AUTOSAR XML (schema 4-2-2)
standard types defined: boolean, float32, float64, sint16, sint32, sint64, sint8, uint16, uint32, uint64, uint8, void
package /BSW/ImplementationDataTypes
  57 x impl type:
    Dcm_ConfirmationStatusType: compu {0x00=DCM_RES_POS_OK, 0x01=DCM_RES_POS_NOT_OK, 0x02=DCM_RES_NEG_OK, 0x03=DCM_RES_NEG_NOT_OK}, implementation-data-type=uint8
    Dcm_DataElement_DspData_0xF010_0Type: implementation-data-type=Dcm_DataElement_DspData_0xF010_0_ArrayType
    Dcm_DataElement_DspData_0xF010_0_ArrayType: category=ARRAY
      element SubElement: array-size=4, array-size-semantics=FIXED-SIZE, implementation-data-type=uint8
    Dcm_DataElement_DspData_0xF110_0Type: implementation-data-type=Dcm_DataElement_DspData_0xF110_0_ArrayType
    Dcm_DataElement_DspData_0xF110_0_ArrayType: category=ARRAY
      element SubElement: array-size=11, array-size-semantics=FIXED-SIZE, implementation-data-type=uint8
    Dcm_DataElement_DspData_0xF111_0Type: implementation-data-type=Dcm_DataElement_DspData_0xF111_0_ArrayType
    Dcm_DataElement_DspData_0xF111_0_ArrayType: category=ARRAY
      element SubElement: array-size=2, array-size-semantics=FIXED-SIZE, implementation-data-type=uint8
    Dcm_DataElement_DspData_0xF118_0Type: implementation-data-type=Dcm_DataElement_DspData_0xF118_0_ArrayType
    Dcm_DataElement_DspData_0xF118_0_ArrayType: category=ARRAY
      element SubElement: array-size=11, array-size-semantics=FIXED-SIZE, implementation-data-type=uint8
    Dcm_DataElement_DspData_0xF119_0Type: implementation-data-type=Dcm_DataElement_DspData_0xF119_0_ArrayType
    Dcm_DataElement_DspData_0xF119_0_ArrayType: category=ARRAY
      element SubElement: array-size=2, array-size-semantics=FIXED-SIZE, implementation-data-type=uint8
    Dcm_DataElement_DspData_0xF150_0Type: implementation-data-type=Dcm_DataElement_DspData_0xF150_0_ArrayType
    Dcm_DataElement_DspData_0xF150_0_ArrayType: category=ARRAY
      element SubElement: array-size=3, array-size-semantics=FIXED-SIZE, implementation-data-type=uint8
    Dcm_DataElement_DspData_0xF15B_0Type: implementation-data-type=Dcm_DataElement_DspData_0xF15B_0_ArrayType
    Dcm_DataElement_DspData_0xF15B_0_ArrayType: category=ARRAY
      element SubElement: array-size=12, array-size-semantics=FIXED-SIZE, implementation-data-type=uint8
    Dcm_DataElement_DspData_0xF186_0Type: implementation-data-type=Dcm_DataElement_DspData_0xF186_0_PrimitiveType
    Dcm_DataElement_DspData_0xF186_0_PrimitiveType: category=VALUE, base-type=uint8
    Dcm_DataElement_DspData_0xF18A_0Type: implementation-data-type=Dcm_DataElement_DspData_0xF18A_0_ArrayType
    Dcm_DataElement_DspData_0xF18A_0_ArrayType: category=ARRAY
      element SubElement: array-size=8, array-size-semantics=FIXED-SIZE, implementation-data-type=uint8
    Dcm_DataElement_DspData_0xF18B_0Type: implementation-data-type=Dcm_DataElement_DspData_0xF18B_0_ArrayType
    Dcm_DataElement_DspData_0xF18B_0_ArrayType: category=ARRAY
      element SubElement: array-size=3, array-size-semantics=FIXED-SIZE, implementation-data-type=uint8
    Dcm_DataElement_DspData_0xF18C_0Type: implementation-data-type=Dcm_DataElement_DspData_0xF18C_0_ArrayType
    Dcm_DataElement_DspData_0xF18C_0_ArrayType: category=ARRAY
      element SubElement: array-size=16, array-size-semantics=FIXED-SIZE, implementation-data-type=uint8
    Dcm_DataElement_DspData_0xF193_0Type: implementation-data-type=Dcm_DataElement_DspData_0xF193_0_ArrayType
    Dcm_DataElement_DspData_0xF193_0_ArrayType: category=ARRAY
      element SubElement: array-size=3, array-size-semantics=FIXED-SIZE, implementation-data-type=uint8
    Dcm_DataElement_DspData_0xF195_0Type: implementation-data-type=Dcm_DataElement_DspData_0xF195_0_ArrayType
    Dcm_DataElement_DspData_0xF195_0_ArrayType: category=ARRAY
      element SubElement: array-size=3, array-size-semantics=FIXED-SIZE, implementation-data-type=uint8
    Dcm_DataElement_DspData_0xF19E_0Type: implementation-data-type=Dcm_DataElement_DspData_0xF19E_0_ArrayType
    Dcm_DataElement_DspData_0xF19E_0_ArrayType: category=ARRAY
      element SubElement: array-size=3, array-size-semantics=FIXED-SIZE, implementation-data-type=uint8
    Dcm_DataElement_DspData_0xFD00_0Type: implementation-data-type=Dcm_DataElement_DspData_0xFD00_0_ArrayType
    Dcm_DataElement_DspData_0xFD00_0_ArrayType: category=ARRAY
      element SubElement: array-size=3, array-size-semantics=FIXED-SIZE, implementation-data-type=uint8
    Dcm_DataElement_DspData_0xFD01_0Type: implementation-data-type=Dcm_DataElement_DspData_0xFD01_0_ArrayType
    Dcm_DataElement_DspData_0xFD01_0_ArrayType: category=ARRAY
      element SubElement: array-size=3, array-size-semantics=FIXED-SIZE, implementation-data-type=uint8
    Dcm_DataElement_DspData_0xFD02_0Type: implementation-data-type=Dcm_DataElement_DspData_0xFD02_0_ArrayType
    Dcm_DataElement_DspData_0xFD02_0_ArrayType: category=ARRAY
      element SubElement: array-size=3, array-size-semantics=FIXED-SIZE, implementation-data-type=uint8
    Dcm_DataElement_DspData_0xFD03_0Type: implementation-data-type=Dcm_DataElement_DspData_0xFD03_0_ArrayType
    Dcm_DataElement_DspData_0xFD03_0_ArrayType: category=ARRAY
      element SubElement: array-size=2, array-size-semantics=FIXED-SIZE, implementation-data-type=uint8
    Dcm_DataElement_DspData_0xFD05_0Type: implementation-data-type=Dcm_DataElement_DspData_0xFD05_0_ArrayType
    Dcm_DataElement_DspData_0xFD05_0_ArrayType: category=ARRAY
      element SubElement: array-size=6, array-size-semantics=FIXED-SIZE, implementation-data-type=uint8
    Dcm_DataElement_DspData_0xFD06_0Type: implementation-data-type=Dcm_DataElement_DspData_0xFD06_0_ArrayType
    Dcm_DataElement_DspData_0xFD06_0_ArrayType: category=ARRAY
      element SubElement: array-size=8, array-size-semantics=FIXED-SIZE, implementation-data-type=uint8
    Dcm_DidSupportedType: compu {0=DCM_DID_SUPPORTED, 1=DCM_DID_NOT_SUPPORTED}, implementation-data-type=uint8
    Dcm_KeyArray_L2Type: category=ARRAY
      element SubElement: array-size=4, array-size-semantics=FIXED-SIZE, implementation-data-type=uint8
    Dcm_NegativeResponseCodeType:
      compu {0x00=DCM_POS_RESP, 0x10=DCM_E_GENERALREJECT, 0x11=DCM_E_SERVICENOTSUPPORTED, 0x12=DCM_E_SUBFUNCTIONNOTSUPPORTED, 0x13=DCM_E_INCORRECTMESSAGELENGTHORINVALIDFORMAT, 0x14=DCM_E_RESPONSETOOLONG, 0x21=DCM_E_BUSYREPEATREQUEST, 0x22=DCM_E_CONDITIONSNOTCORRECT, 0x24=DCM_E_REQUESTSEQUENCEERROR, 0x25=DCM_E_NORESPONSEFROMSUBNETCOMPONENT, 0x26=DCM_E_FAILUREPREVENTSEXECUTIONOFREQUESTEDACTION, 0x31=DCM_E_REQUESTOUTOFRANGE, 0x33=DCM_E_SECURITYACCESSDENIED, 0x35=DCM_E_INVALIDKEY, 0x36=DCM_E_EXCEEDNUMBEROFATTEMPTS, 0x37=DCM_E_REQUIREDTIMEDELAYNOTEXPIRED, 0x70=DCM_E_UPLOADDOWNLOADNOTACCEPTED, 0x71=DCM_E_TRANSFERDATASUSPENDED, 0x72=DCM_E_GENERALPROGRAMMINGFAILURE, 0x73=DCM_E_WRONGBLOCKSEQUENCECOUNTER, 0x7E=DCM_E_SUBFUNCTIONNOTSUPPORTEDINACTIVESESSION, 0x7F=DCM_E_SERVICENOTSUPPORTEDINACTIVESESSION, 0x81=DCM_E_RPMTOOHIGH, 0x82=DCM_E_RPMTOOLOW, 0x83=DCM_E_ENGINEISRUNNING, 0x84=DCM_E_ENGINEISNOTRUNNING, 0x85=DCM_E_ENGINERUNTIMETOOLOW, 0x86=DCM_E_TEMPERATURETOOHIGH, 0x87=DCM_E_TEMPERATURETOOLOW, 0x88=DCM_E_VEHICLESPEEDTOOHIGH, 0x89=DCM_E_VEHICLESPEEDTOOLOW, 0x8A=DCM_E_THROTTLE_PEDALTOOHIGH, 0x8B=DCM_E_THROTTLE_PEDALTOOLOW, 0x8C=DCM_E_TRANSMISSIONRANGENOTINNEUTRAL, 0x8D=DCM_E_TRANSMISSIONRANGENOTINGEAR, 0x8F=DCM_E_BRAKESWITCH_NOTCLOSED, 0x90=DCM_E_SHIFTERLEVERNOTINPARK, 0x91=DCM_E_TORQUECONVERTERCLUTCHLOCKED, 0x92=DCM_E_VOLTAGETOOHIGH, 0x93=DCM_E_VOLTAGETOOLOW, 0xF0=DCM_E_VMSCNC_0, 0xF1=DCM_E_VMSCNC_1, 0xF2=DCM_E_VMSCNC_2, 0xF3=DCM_E_VMSCNC_3, 0xF4=DCM_E_VMSCNC_4, 0xF5=DCM_E_VMSCNC_5, 0xF6=DCM_E_VMSCNC_6, 0xF7=DCM_E_VMSCNC_7, 0xF8=DCM_E_VMSCNC_8, 0xF9=DCM_E_VMSCNC_9, 0xFA=DCM_E_VMSCNC_A, 0xFB=DCM_E_VMSCNC_B, 0xFC=DCM_E_VMSCNC_C, 0xFD=DCM_E_VMSCNC_D, 0xFE=DCM_E_VMSCNC_E}
      range raw 0x00..0xFF
      implementation-data-type=uint8
    Dcm_OpStatusType: compu {0x00=DCM_INITIAL, 0x01=DCM_PENDING, 0x02=DCM_CANCEL, 0x03=DCM_FORCE_RCRRP_OK}, implementation-data-type=uint8
    Dcm_ProtocolType: compu {0x00=DCM_OBD_ON_CAN, 0x01=DCM_OBD_ON_FLEXRAY, 0x02=DCM_OBD_ON_IP, 0x03=DCM_UDS_ON_CAN, 0x04=DCM_UDS_ON_FLEXRAY, 0x05=DCM_UDS_ON_IP, 0x06=DCM_ROE_ON_CAN, 0x07=DCM_ROE_ON_FLEXRAY, 0x08=DCM_ROE_ON_IP, 0x09=DCM_PERIODICTRANS_ON_CAN, 0x0A=DCM_PERIODICTRANS_ON_FLEXRAY, 0x0B=DCM_PERIODICTRANS_ON_IP, 0x0C=DCM_NO_ACTIVE_PROTOCOL, 0x0D=DCM_UDS_ON_LIN, 0xF0=DCM_SUPPLIER_1, 0xF1=DCM_SUPPLIER_2, 0xF2=DCM_SUPPLIER_3, 0xF3=DCM_SUPPLIER_4, 0xF4=DCM_SUPPLIER_5, 0xF5=DCM_SUPPLIER_6, 0xF6=DCM_SUPPLIER_7, 0xF7=DCM_SUPPLIER_8, 0xF8=DCM_SUPPLIER_9, 0xF9=DCM_SUPPLIER_10, 0xFA=DCM_SUPPLIER_11, 0xFB=DCM_SUPPLIER_12, 0xFC=DCM_SUPPLIER_13, 0xFD=DCM_SUPPLIER_14, 0xFE=DCM_SUPPLIER_15}, implementation-data-type=uint8
    Dcm_SecLevelType: compu {0=DCM_SEC_LEV_LOCKED, 2=DCM_SEC_LEV_L2, 255=DCM_SEC_LEV_ALL}, range raw 0..255, implementation-data-type=uint8
    Dcm_SeedArray_L2Type: category=ARRAY
      element SubElement: array-size=4, array-size-semantics=FIXED-SIZE, implementation-data-type=uint8
    Dcm_SesCtrlType: compu {1=DCM_DEFAULT_SESSION, 2=DCM_PROGRAMMING_SESSION, 3=DCM_EXTENDED_DIAGNOSTIC_SESSION, 102=DCM_FACTORYTEST_SESSION}, implementation-data-type=uint8
    Dcm_StartDataOut_DspRoutine0x0203_DspRoutine0x0203_StartOutSignalPrimitiveType: category=VALUE, base-type=uint8
    Dcm_StartDataOut_DspRoutine0x0203_DspRoutine0x0203_StartOutSignalType: implementation-data-type=Dcm_StartDataOut_DspRoutine0x0203_DspRoutine0x0203_StartOutSignalPrimitiveType
    Dcm_StartFlexibleInArrayData_DspRoutine0xFD04_DspRoutine0xFD04_StartInSignalType: category=ARRAY
      element SubElement: array-size=3, array-size-semantics=FIXED-SIZE, implementation-data-type=uint8
    Dcm_StartFlexibleInArrayData_DspRoutine0xFD05_DspRoutine0xFD05_StartInSignalType: category=ARRAY
      element SubElement: array-size=2, array-size-semantics=FIXED-SIZE, implementation-data-type=uint8
    Dcm_StartFlexibleOutArrayData_DspRoutine0xFD04_DspRoutine0xFD04_StartOutSignalType: category=ARRAY
      element SubElement: array-size=3, array-size-semantics=FIXED-SIZE, implementation-data-type=uint8
    Dcm_StartFlexibleOutArrayData_DspRoutine0xFD05_DspRoutine0xFD05_StartOutSignalType: category=ARRAY
      element SubElement: array-size=2, array-size-semantics=FIXED-SIZE, implementation-data-type=uint8
    Dcm_StopFlexibleInArrayData_DspRoutine0xFD04_DspRoutine0xFD04_StopInSignalType: category=ARRAY
      element SubElement: array-size=3, array-size-semantics=FIXED-SIZE, implementation-data-type=uint8
    Dcm_StopFlexibleOutArrayData_DspRoutine0xFD04_DspRoutine0xFD04_StopOutSignalType: category=ARRAY
      element SubElement: array-size=3, array-size-semantics=FIXED-SIZE, implementation-data-type=uint8
package /BSW/ModeDeclarationGroups
  5 x mode declaration group, all with category=EXPLICIT_ORDER:
    DcmCommunicationControl_ComM_BODY_LE1_CAN: initial-mode=DCM_ENABLE_RX_TX_NORM_NM, on-transition-value=12
      12 x mode:
        DCM_DISABLE_RX_ENABLE_TX_NM: value=6
        DCM_DISABLE_RX_ENABLE_TX_NORM: value=2
        DCM_DISABLE_RX_ENABLE_TX_NORM_NM: value=10
        DCM_DISABLE_RX_TX_NM: value=7
        DCM_DISABLE_RX_TX_NORMAL: value=3
        DCM_DISABLE_RX_TX_NORM_NM: value=11
        DCM_ENABLE_RX_DISABLE_TX_NM: value=5
        DCM_ENABLE_RX_DISABLE_TX_NORM: value=1
        DCM_ENABLE_RX_DISABLE_TX_NORM_NM: value=9
        DCM_ENABLE_RX_TX_NM: value=4
        DCM_ENABLE_RX_TX_NORM: value=0
        DCM_ENABLE_RX_TX_NORM_NM: value=8
    DcmControlDtcSetting: initial-mode=ENABLEDTCSETTING, on-transition-value=2
      mode DISABLEDTCSETTING: value=1
      mode ENABLEDTCSETTING: value=0
    DcmDiagnosticSessionControl: initial-mode=DEFAULT_SESSION, on-transition-value=4
      4 x mode:
        DEFAULT_SESSION: value=0
        EXTENDED_DIAGNOSTIC_SESSION: value=2
        FACTORYTEST_SESSION: value=3
        PROGRAMMING_SESSION: value=1
    DcmEcuReset: initial-mode=NONE, on-transition-value=7
      7 x mode:
        EXECUTE: value=6
        HARD: value=1
        JUMPTOBOOTLOADER: value=4
        JUMPTOSYSSUPPLIERBOOTLOADER: value=5
        KEYONOFF: value=2
        NONE: value=0
        SOFT: value=3
    DcmSecurityAccess: initial-mode=SEC_LEV_LOCKED, on-transition-value=1
      mode SEC_LEV_LOCKED: value=0
package /BSW/PortInterfaces
  27 x client server interface, all with service-kind=DIAGNOSTIC-COMMUNICATION-MANAGER:
    CallbackDCMRequestServices
      operation StartProtocol: possible-error=[CallbackDCMRequestServices/E_NOT_OK, CallbackDCMRequestServices/E_OK, E_PROTOCOL_NOT_ALLOWED]
        arg ProtocolType: type=Dcm_ProtocolType, direction=IN
        arg TesterSourceAddress: type=uint16, direction=IN
        arg ConnectionId: type=uint16, direction=IN
      operation StopProtocol: possible-error=[CallbackDCMRequestServices/E_NOT_OK, CallbackDCMRequestServices/E_OK]
        arg ProtocolType: type=Dcm_ProtocolType, direction=IN
        arg TesterSourceAddress: type=uint16, direction=IN
        arg ConnectionId: type=uint16, direction=IN
      error E_NOT_OK: error-code=1
      error E_OK: error-code=0
      error E_PROTOCOL_NOT_ALLOWED: error-code=5
    DCMServices
      4 x operation:
        GetSecurityLevel: possible-error=[DCMServices/E_NOT_OK, DCMServices/E_OK]
          arg SecLevel: type=Dcm_SecLevelType, direction=OUT
        GetSesCtrlType: possible-error=[DCMServices/E_NOT_OK, DCMServices/E_OK]
          arg SesCtrlType: type=Dcm_SesCtrlType, direction=OUT
        ResetToDefaultSession: possible-error=[DCMServices/E_NOT_OK, DCMServices/E_OK]
        SetActiveDiagnostic: possible-error=DCMServices/E_OK
          arg active: type=boolean, direction=IN
      error E_NOT_OK: error-code=1
      error E_OK: error-code=0
    DataServices_DspData_0xF010_0
      operation ReadData: possible-error=[DataServices_DspData_0xF010_0/DCM_E_PENDING, DataServices_DspData_0xF010_0/E_NOT_OK, DataServices_DspData_0xF010_0/E_OK]
        arg OpStatus: type=Dcm_OpStatusType, direction=IN
        arg Data: type=Dcm_DataElement_DspData_0xF010_0Type, direction=OUT
        arg ErrorCode: type=Dcm_NegativeResponseCodeType, direction=OUT
      error DCM_E_PENDING: error-code=10
      error E_NOT_OK: error-code=1
      error E_OK: error-code=0
    DataServices_DspData_0xF110_0
      operation ReadData: possible-error=[DataServices_DspData_0xF110_0/DCM_E_PENDING, DataServices_DspData_0xF110_0/E_NOT_OK, DataServices_DspData_0xF110_0/E_OK]
        arg OpStatus: type=Dcm_OpStatusType, direction=IN
        arg Data: type=Dcm_DataElement_DspData_0xF110_0Type, direction=OUT
        arg ErrorCode: type=Dcm_NegativeResponseCodeType, direction=OUT
      error DCM_E_PENDING: error-code=10
      error E_NOT_OK: error-code=1
      error E_OK: error-code=0
    DataServices_DspData_0xF111_0
      operation ReadData: possible-error=[DataServices_DspData_0xF111_0/DCM_E_PENDING, DataServices_DspData_0xF111_0/E_NOT_OK, DataServices_DspData_0xF111_0/E_OK]
        arg OpStatus: type=Dcm_OpStatusType, direction=IN
        arg Data: type=Dcm_DataElement_DspData_0xF111_0Type, direction=OUT
        arg ErrorCode: type=Dcm_NegativeResponseCodeType, direction=OUT
      error DCM_E_PENDING: error-code=10
      error E_NOT_OK: error-code=1
      error E_OK: error-code=0
    DataServices_DspData_0xF118_0
      operation ReadData: possible-error=[DataServices_DspData_0xF118_0/DCM_E_PENDING, DataServices_DspData_0xF118_0/E_NOT_OK, DataServices_DspData_0xF118_0/E_OK]
        arg OpStatus: type=Dcm_OpStatusType, direction=IN
        arg Data: type=Dcm_DataElement_DspData_0xF118_0Type, direction=OUT
        arg ErrorCode: type=Dcm_NegativeResponseCodeType, direction=OUT
      error DCM_E_PENDING: error-code=10
      error E_NOT_OK: error-code=1
      error E_OK: error-code=0
    DataServices_DspData_0xF119_0
      operation ReadData: possible-error=[DataServices_DspData_0xF119_0/DCM_E_PENDING, DataServices_DspData_0xF119_0/E_NOT_OK, DataServices_DspData_0xF119_0/E_OK]
        arg OpStatus: type=Dcm_OpStatusType, direction=IN
        arg Data: type=Dcm_DataElement_DspData_0xF119_0Type, direction=OUT
        arg ErrorCode: type=Dcm_NegativeResponseCodeType, direction=OUT
      error DCM_E_PENDING: error-code=10
      error E_NOT_OK: error-code=1
      error E_OK: error-code=0
    DataServices_DspData_0xF150_0
      operation ReadData: possible-error=[DataServices_DspData_0xF150_0/DCM_E_PENDING, DataServices_DspData_0xF150_0/E_NOT_OK, DataServices_DspData_0xF150_0/E_OK]
        arg OpStatus: type=Dcm_OpStatusType, direction=IN
        arg Data: type=Dcm_DataElement_DspData_0xF150_0Type, direction=OUT
        arg ErrorCode: type=Dcm_NegativeResponseCodeType, direction=OUT
      error DCM_E_PENDING: error-code=10
      error E_NOT_OK: error-code=1
      error E_OK: error-code=0
    DataServices_DspData_0xF15B_0
      operation ReadData: possible-error=[DataServices_DspData_0xF15B_0/DCM_E_PENDING, DataServices_DspData_0xF15B_0/E_NOT_OK, DataServices_DspData_0xF15B_0/E_OK]
        arg OpStatus: type=Dcm_OpStatusType, direction=IN
        arg Data: type=Dcm_DataElement_DspData_0xF15B_0Type, direction=OUT
        arg ErrorCode: type=Dcm_NegativeResponseCodeType, direction=OUT
      error DCM_E_PENDING: error-code=10
      error E_NOT_OK: error-code=1
      error E_OK: error-code=0
    DataServices_DspData_0xF186_0
      operation ReadData: possible-error=[DataServices_DspData_0xF186_0/DCM_E_PENDING, DataServices_DspData_0xF186_0/E_NOT_OK, DataServices_DspData_0xF186_0/E_OK]
        arg OpStatus: type=Dcm_OpStatusType, direction=IN
        arg Data: type=Dcm_DataElement_DspData_0xF186_0Type, direction=OUT
        arg ErrorCode: type=Dcm_NegativeResponseCodeType, direction=OUT
      error DCM_E_PENDING: error-code=10
      error E_NOT_OK: error-code=1
      error E_OK: error-code=0
    DataServices_DspData_0xF18A_0
      operation ReadData: possible-error=[DataServices_DspData_0xF18A_0/DCM_E_PENDING, DataServices_DspData_0xF18A_0/E_NOT_OK, DataServices_DspData_0xF18A_0/E_OK]
        arg OpStatus: type=Dcm_OpStatusType, direction=IN
        arg Data: type=Dcm_DataElement_DspData_0xF18A_0Type, direction=OUT
        arg ErrorCode: type=Dcm_NegativeResponseCodeType, direction=OUT
      error DCM_E_PENDING: error-code=10
      error E_NOT_OK: error-code=1
      error E_OK: error-code=0
    DataServices_DspData_0xF18B_0
      operation ReadData: possible-error=[DataServices_DspData_0xF18B_0/DCM_E_PENDING, DataServices_DspData_0xF18B_0/E_NOT_OK, DataServices_DspData_0xF18B_0/E_OK]
        arg OpStatus: type=Dcm_OpStatusType, direction=IN
        arg Data: type=Dcm_DataElement_DspData_0xF18B_0Type, direction=OUT
        arg ErrorCode: type=Dcm_NegativeResponseCodeType, direction=OUT
      operation WriteData: possible-error=[DataServices_DspData_0xF18B_0/DCM_E_PENDING, DataServices_DspData_0xF18B_0/E_NOT_OK, DataServices_DspData_0xF18B_0/E_OK]
        arg Data: type=Dcm_DataElement_DspData_0xF18B_0Type, direction=IN
        arg OpStatus: type=Dcm_OpStatusType, direction=IN
        arg ErrorCode: type=Dcm_NegativeResponseCodeType, direction=OUT
      error DCM_E_PENDING: error-code=10
      error E_NOT_OK: error-code=1
      error E_OK: error-code=0
    DataServices_DspData_0xF18C_0
      operation ReadData: possible-error=[DataServices_DspData_0xF18C_0/DCM_E_PENDING, DataServices_DspData_0xF18C_0/E_NOT_OK, DataServices_DspData_0xF18C_0/E_OK]
        arg OpStatus: type=Dcm_OpStatusType, direction=IN
        arg Data: type=Dcm_DataElement_DspData_0xF18C_0Type, direction=OUT
        arg ErrorCode: type=Dcm_NegativeResponseCodeType, direction=OUT
      operation WriteData: possible-error=[DataServices_DspData_0xF18C_0/DCM_E_PENDING, DataServices_DspData_0xF18C_0/E_NOT_OK, DataServices_DspData_0xF18C_0/E_OK]
        arg Data: type=Dcm_DataElement_DspData_0xF18C_0Type, direction=IN
        arg OpStatus: type=Dcm_OpStatusType, direction=IN
        arg ErrorCode: type=Dcm_NegativeResponseCodeType, direction=OUT
      error DCM_E_PENDING: error-code=10
      error E_NOT_OK: error-code=1
      error E_OK: error-code=0
    DataServices_DspData_0xF193_0
      operation ReadData: possible-error=[DataServices_DspData_0xF193_0/DCM_E_PENDING, DataServices_DspData_0xF193_0/E_NOT_OK, DataServices_DspData_0xF193_0/E_OK]
        arg OpStatus: type=Dcm_OpStatusType, direction=IN
        arg Data: type=Dcm_DataElement_DspData_0xF193_0Type, direction=OUT
        arg ErrorCode: type=Dcm_NegativeResponseCodeType, direction=OUT
      error DCM_E_PENDING: error-code=10
      error E_NOT_OK: error-code=1
      error E_OK: error-code=0
    DataServices_DspData_0xF195_0
      operation ReadData: possible-error=[DataServices_DspData_0xF195_0/DCM_E_PENDING, DataServices_DspData_0xF195_0/E_NOT_OK, DataServices_DspData_0xF195_0/E_OK]
        arg OpStatus: type=Dcm_OpStatusType, direction=IN
        arg Data: type=Dcm_DataElement_DspData_0xF195_0Type, direction=OUT
        arg ErrorCode: type=Dcm_NegativeResponseCodeType, direction=OUT
      error DCM_E_PENDING: error-code=10
      error E_NOT_OK: error-code=1
      error E_OK: error-code=0
    DataServices_DspData_0xF19E_0
      operation ReadData: possible-error=[DataServices_DspData_0xF19E_0/DCM_E_PENDING, DataServices_DspData_0xF19E_0/E_NOT_OK, DataServices_DspData_0xF19E_0/E_OK]
        arg OpStatus: type=Dcm_OpStatusType, direction=IN
        arg Data: type=Dcm_DataElement_DspData_0xF19E_0Type, direction=OUT
        arg ErrorCode: type=Dcm_NegativeResponseCodeType, direction=OUT
      error DCM_E_PENDING: error-code=10
      error E_NOT_OK: error-code=1
      error E_OK: error-code=0
    DataServices_DspData_0xFD00_0
      operation ReadData: possible-error=[DataServices_DspData_0xFD00_0/DCM_E_PENDING, DataServices_DspData_0xFD00_0/E_NOT_OK, DataServices_DspData_0xFD00_0/E_OK]
        arg OpStatus: type=Dcm_OpStatusType, direction=IN
        arg Data: type=Dcm_DataElement_DspData_0xFD00_0Type, direction=OUT
        arg ErrorCode: type=Dcm_NegativeResponseCodeType, direction=OUT
      error DCM_E_PENDING: error-code=10
      error E_NOT_OK: error-code=1
      error E_OK: error-code=0
    DataServices_DspData_0xFD01_0
      operation ReadData: possible-error=[DataServices_DspData_0xFD01_0/DCM_E_PENDING, DataServices_DspData_0xFD01_0/E_NOT_OK, DataServices_DspData_0xFD01_0/E_OK]
        arg OpStatus: type=Dcm_OpStatusType, direction=IN
        arg Data: type=Dcm_DataElement_DspData_0xFD01_0Type, direction=OUT
        arg ErrorCode: type=Dcm_NegativeResponseCodeType, direction=OUT
      error DCM_E_PENDING: error-code=10
      error E_NOT_OK: error-code=1
      error E_OK: error-code=0
    DataServices_DspData_0xFD02_0
      operation ReadData: possible-error=[DataServices_DspData_0xFD02_0/DCM_E_PENDING, DataServices_DspData_0xFD02_0/E_NOT_OK, DataServices_DspData_0xFD02_0/E_OK]
        arg OpStatus: type=Dcm_OpStatusType, direction=IN
        arg Data: type=Dcm_DataElement_DspData_0xFD02_0Type, direction=OUT
        arg ErrorCode: type=Dcm_NegativeResponseCodeType, direction=OUT
      error DCM_E_PENDING: error-code=10
      error E_NOT_OK: error-code=1
      error E_OK: error-code=0
    DataServices_DspData_0xFD03_0
      operation ReadData: possible-error=[DataServices_DspData_0xFD03_0/DCM_E_PENDING, DataServices_DspData_0xFD03_0/E_NOT_OK, DataServices_DspData_0xFD03_0/E_OK]
        arg OpStatus: type=Dcm_OpStatusType, direction=IN
        arg Data: type=Dcm_DataElement_DspData_0xFD03_0Type, direction=OUT
        arg ErrorCode: type=Dcm_NegativeResponseCodeType, direction=OUT
      error DCM_E_PENDING: error-code=10
      error E_NOT_OK: error-code=1
      error E_OK: error-code=0
    DataServices_DspData_0xFD05_0
      operation ReadData: possible-error=[DataServices_DspData_0xFD05_0/DCM_E_PENDING, DataServices_DspData_0xFD05_0/E_NOT_OK, DataServices_DspData_0xFD05_0/E_OK]
        arg OpStatus: type=Dcm_OpStatusType, direction=IN
        arg Data: type=Dcm_DataElement_DspData_0xFD05_0Type, direction=OUT
        arg ErrorCode: type=Dcm_NegativeResponseCodeType, direction=OUT
      error DCM_E_PENDING: error-code=10
      error E_NOT_OK: error-code=1
      error E_OK: error-code=0
    DataServices_DspData_0xFD06_0
      operation ReadData: possible-error=[DataServices_DspData_0xFD06_0/DCM_E_PENDING, DataServices_DspData_0xFD06_0/E_NOT_OK, DataServices_DspData_0xFD06_0/E_OK]
        arg OpStatus: type=Dcm_OpStatusType, direction=IN
        arg Data: type=Dcm_DataElement_DspData_0xFD06_0Type, direction=OUT
        arg ErrorCode: type=Dcm_NegativeResponseCodeType, direction=OUT
      error DCM_E_PENDING: error-code=10
      error E_NOT_OK: error-code=1
      error E_OK: error-code=0
    RoutineServices_0x0203
      operation Start: possible-error=[RoutineServices_0x0203/DCM_E_FORCE_RCRRP, RoutineServices_0x0203/DCM_E_PENDING, RoutineServices_0x0203/E_NOT_OK, RoutineServices_0x0203/E_OK]
        arg OpStatus: type=Dcm_OpStatusType, direction=IN
        arg DataOut_DspRoutine0x0203_StartOutSignal: type=Dcm_StartDataOut_DspRoutine0x0203_DspRoutine0x0203_StartOutSignalType, direction=OUT
        arg ErrorCode: type=Dcm_NegativeResponseCodeType, direction=OUT
      4 x error:
        DCM_E_FORCE_RCRRP: error-code=12
        DCM_E_PENDING: error-code=10
        E_NOT_OK: error-code=1
        E_OK: error-code=0
    RoutineServices_0xFD04
      operation Start: possible-error=[RoutineServices_0xFD04/DCM_E_FORCE_RCRRP, RoutineServices_0xFD04/DCM_E_PENDING, RoutineServices_0xFD04/E_NOT_OK, RoutineServices_0xFD04/E_OK]
        5 x arg:
          DataIn_DspRoutine0xFD04_StartInSignal: type=Dcm_StartFlexibleInArrayData_DspRoutine0xFD04_DspRoutine0xFD04_StartInSignalType, direction=IN
          OpStatus: type=Dcm_OpStatusType, direction=IN
          DataOut_DspRoutine0xFD04_StartOutSignal: type=Dcm_StartFlexibleOutArrayData_DspRoutine0xFD04_DspRoutine0xFD04_StartOutSignalType, direction=OUT
          currentDataLength: type=uint16, direction=INOUT
          ErrorCode: type=Dcm_NegativeResponseCodeType, direction=OUT
      operation Stop: possible-error=[RoutineServices_0xFD04/DCM_E_FORCE_RCRRP, RoutineServices_0xFD04/DCM_E_PENDING, RoutineServices_0xFD04/E_NOT_OK, RoutineServices_0xFD04/E_OK]
        5 x arg:
          DataIn_DspRoutine0xFD04_StopInSignal: type=Dcm_StopFlexibleInArrayData_DspRoutine0xFD04_DspRoutine0xFD04_StopInSignalType, direction=IN
          OpStatus: type=Dcm_OpStatusType, direction=IN
          DataOut_DspRoutine0xFD04_StopOutSignal: type=Dcm_StopFlexibleOutArrayData_DspRoutine0xFD04_DspRoutine0xFD04_StopOutSignalType, direction=OUT
          currentDataLength: type=uint16, direction=INOUT
          ErrorCode: type=Dcm_NegativeResponseCodeType, direction=OUT
      4 x error:
        DCM_E_FORCE_RCRRP: error-code=12
        DCM_E_PENDING: error-code=10
        E_NOT_OK: error-code=1
        E_OK: error-code=0
    RoutineServices_0xFD05
      operation Start: possible-error=[RoutineServices_0xFD05/DCM_E_FORCE_RCRRP, RoutineServices_0xFD05/DCM_E_PENDING, RoutineServices_0xFD05/E_NOT_OK, RoutineServices_0xFD05/E_OK]
        5 x arg:
          DataIn_DspRoutine0xFD05_StartInSignal: type=Dcm_StartFlexibleInArrayData_DspRoutine0xFD05_DspRoutine0xFD05_StartInSignalType, direction=IN
          OpStatus: type=Dcm_OpStatusType, direction=IN
          DataOut_DspRoutine0xFD05_StartOutSignal: type=Dcm_StartFlexibleOutArrayData_DspRoutine0xFD05_DspRoutine0xFD05_StartOutSignalType, direction=OUT
          currentDataLength: type=uint16, direction=INOUT
          ErrorCode: type=Dcm_NegativeResponseCodeType, direction=OUT
      4 x error:
        DCM_E_FORCE_RCRRP: error-code=12
        DCM_E_PENDING: error-code=10
        E_NOT_OK: error-code=1
        E_OK: error-code=0
    RoutineServices_0xFD10
      operation Start: possible-error=[RoutineServices_0xFD10/DCM_E_FORCE_RCRRP, RoutineServices_0xFD10/DCM_E_PENDING, RoutineServices_0xFD10/E_NOT_OK, RoutineServices_0xFD10/E_OK]
        arg OpStatus: type=Dcm_OpStatusType, direction=IN
        arg ErrorCode: type=Dcm_NegativeResponseCodeType, direction=OUT
      4 x error:
        DCM_E_FORCE_RCRRP: error-code=12
        DCM_E_PENDING: error-code=10
        E_NOT_OK: error-code=1
        E_OK: error-code=0
    SecurityAccess_L2
      4 x operation:
        CompareKey: possible-error=[DCM_E_COMPARE_KEY_FAILED, SecurityAccess_L2/DCM_E_PENDING, SecurityAccess_L2/E_NOT_OK, SecurityAccess_L2/E_OK]
          arg Key: type=Dcm_KeyArray_L2Type, direction=IN
          arg OpStatus: type=Dcm_OpStatusType, direction=IN
          arg ErrorCode: type=Dcm_NegativeResponseCodeType, direction=OUT
        GetSecurityAttemptCounter: possible-error=[SecurityAccess_L2/DCM_E_PENDING, SecurityAccess_L2/E_NOT_OK, SecurityAccess_L2/E_OK]
          arg OpStatus: type=Dcm_OpStatusType, direction=IN
          arg AttemptCounter: type=uint8, direction=OUT
        GetSeed: possible-error=[SecurityAccess_L2/DCM_E_PENDING, SecurityAccess_L2/E_NOT_OK, SecurityAccess_L2/E_OK]
          arg OpStatus: type=Dcm_OpStatusType, direction=IN
          arg Seed: type=Dcm_SeedArray_L2Type, direction=OUT
          arg ErrorCode: type=Dcm_NegativeResponseCodeType, direction=OUT
        SetSecurityAttemptCounter: possible-error=[SecurityAccess_L2/DCM_E_PENDING, SecurityAccess_L2/E_NOT_OK, SecurityAccess_L2/E_OK]
          arg OpStatus: type=Dcm_OpStatusType, direction=IN
          arg AttemptCounter: type=uint8, direction=IN
      4 x error:
        DCM_E_COMPARE_KEY_FAILED: error-code=11
        DCM_E_PENDING: error-code=10
        E_NOT_OK: error-code=1
        E_OK: error-code=0
  5 x mode switch interface, all with service-kind=DIAGNOSTIC-COMMUNICATION-MANAGER:
    DcmCommunicationControl_ComM_BODY_LE1_CAN
      mode group DcmCommunicationControl_ComM_BODY_LE1_CAN: type=DcmCommunicationControl_ComM_BODY_LE1_CAN
    DcmControlDtcSetting
      mode group DcmControlDtcSetting: type=DcmControlDtcSetting
    DcmDiagnosticSessionControl
      mode group DcmDiagnosticSessionControl: type=DcmDiagnosticSessionControl
    DcmEcuReset
      mode group DcmEcuReset: type=DcmEcuReset
    DcmSecurityAccess
      mode group DcmSecurityAccess: type=DcmSecurityAccess
package /BSW/SWCs
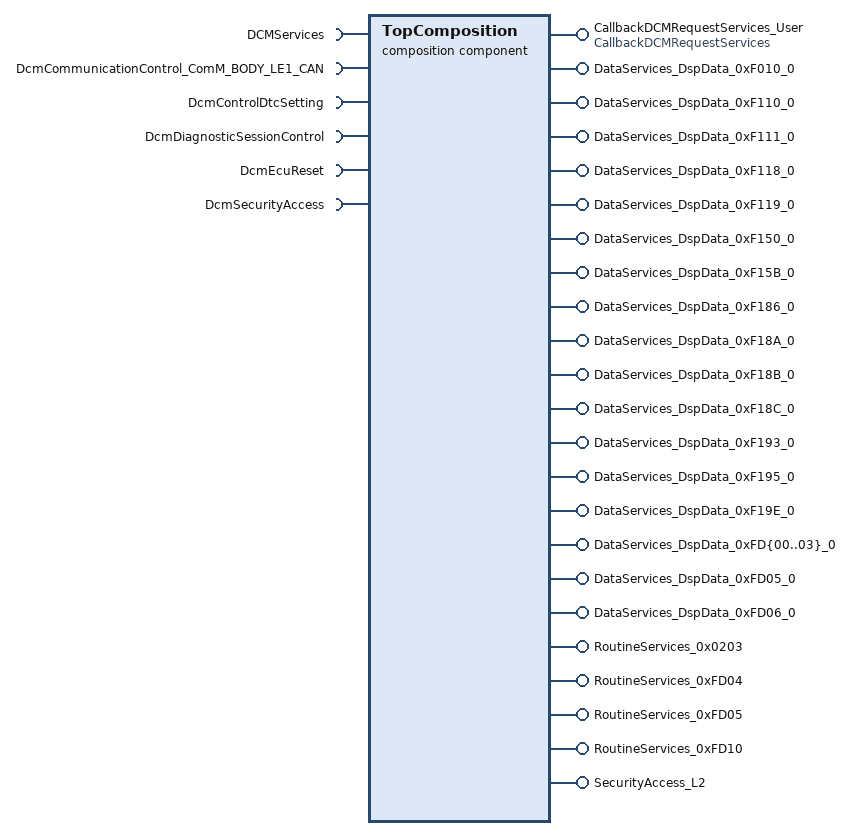
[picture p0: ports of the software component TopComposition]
  composition sw component type TopComposition
    provide port CallbackDCMRequestServices_User: provided-interface=CallbackDCMRequestServices
    require port DCMServices: required-interface=DCMServices
    20 x provide port:
      DataServices_DspData_0xF010_0: provided-interface=DataServices_DspData_0xF010_0
      DataServices_DspData_0xF110_0: provided-interface=DataServices_DspData_0xF110_0
      DataServices_DspData_0xF111_0: provided-interface=DataServices_DspData_0xF111_0
      DataServices_DspData_0xF118_0: provided-interface=DataServices_DspData_0xF118_0
      DataServices_DspData_0xF119_0: provided-interface=DataServices_DspData_0xF119_0
      DataServices_DspData_0xF150_0: provided-interface=DataServices_DspData_0xF150_0
      DataServices_DspData_0xF15B_0: provided-interface=DataServices_DspData_0xF15B_0
      DataServices_DspData_0xF186_0: provided-interface=DataServices_DspData_0xF186_0
      DataServices_DspData_0xF18A_0: provided-interface=DataServices_DspData_0xF18A_0
      DataServices_DspData_0xF18B_0: provided-interface=DataServices_DspData_0xF18B_0
      DataServices_DspData_0xF18C_0: provided-interface=DataServices_DspData_0xF18C_0
      DataServices_DspData_0xF193_0: provided-interface=DataServices_DspData_0xF193_0
      DataServices_DspData_0xF195_0: provided-interface=DataServices_DspData_0xF195_0
      DataServices_DspData_0xF19E_0: provided-interface=DataServices_DspData_0xF19E_0
      DataServices_DspData_0xFD{00..03}_0: provided-interface=DataServices_DspData_0xFD{00..03}_0
      DataServices_DspData_0xFD05_0: provided-interface=DataServices_DspData_0xFD05_0
      DataServices_DspData_0xFD06_0: provided-interface=DataServices_DspData_0xFD06_0
    5 x require port:
      DcmCommunicationControl_ComM_BODY_LE1_CAN: required-interface=DcmCommunicationControl_ComM_BODY_LE1_CAN
      DcmControlDtcSetting: required-interface=DcmControlDtcSetting
      DcmDiagnosticSessionControl: required-interface=DcmDiagnosticSessionControl
      DcmEcuReset: required-interface=DcmEcuReset
      DcmSecurityAccess: required-interface=DcmSecurityAccess
    5 x provide port:
      RoutineServices_0x0203: provided-interface=RoutineServices_0x0203
      RoutineServices_0xFD04: provided-interface=RoutineServices_0xFD04
      RoutineServices_0xFD05: provided-interface=RoutineServices_0xFD05
      RoutineServices_0xFD10: provided-interface=RoutineServices_0xFD10
      SecurityAccess_L2: provided-interface=SecurityAccess_L2
